VERSION "BMW i3 FlexRay custom draft v3"

NS_ :

BS_:

BU_: BMW_I3

CM_ "Draft DBC derived from BMW i3 FlexRay and PT-CAN logs. Address 27 was not observed in any uploaded segment. Signals below intentionally mix three classes: confirmed parse signals already used by CarState, state/proxy helpers useful for reverse engineering, and unresolved TX candidates kept for shadow-debug correlation.";

BO_ 46 WHEEL_SPEED: 17 BMW_I3
 SG_ WHEEL_SPEED_RAW_WORD_A : 8|16@1+ (1,0) [0|65535] "" BMW_I3
 SG_ WHEEL_SPEED_RAW_WORD_B : 24|16@1+ (1,0) [0|65535] "" BMW_I3
 SG_ WHEEL_SPEED_RAW_WORD_C : 40|16@1+ (1,0) [0|65535] "" BMW_I3
 SG_ WHEEL_SPEED_RAW_WORD_D : 56|16@1+ (1,0) [0|65535] "" BMW_I3
 SG_ RL_SPEED_RAW : 24|16@1+ (0.015625,-511.984375) [0|65535] "kph" BMW_I3
 SG_ RR_SPEED_RAW : 40|16@1+ (0.015625,-511.984375) [0|65535] "kph" BMW_I3
 SG_ FL_SPEED_RAW : 56|16@1+ (0.015625,-511.984375) [0|65535] "kph" BMW_I3
 SG_ FR_SPEED_RAW : 72|16@1+ (0.015625,-511.984375) [0|65535] "kph" BMW_I3
 CM_ BO_ 46 "Confirmed BMW-style wheel-speed helper aligned with the SP2018 bit layout. Wheel speeds remain the secondary/fallback vehicle-speed source in current CarState.";

BO_ 49 STEER_TORQUE: 17 BMW_I3
 SG_ STEER_TORQUE_CYCLE_RAW : 0|8@1+ (1,0) [0|255] "" BMW_I3
 SG_ STEER_TORQUE_RAW_WORD_A : 8|16@1+ (1,0) [0|65535] "" BMW_I3
 SG_ STEER_TORQUE_RAW_WORD_B : 24|16@1+ (1,0) [0|65535] "" BMW_I3
 SG_ STEER_TORQUE_RAW_WORD_C : 40|16@1+ (1,0) [0|65535] "" BMW_I3
 SG_ STEER_TORQUE_RAW_WORD_D : 56|16@1+ (1,0) [0|65535] "" BMW_I3
 SG_ DRIVER_STEER_TORQUE_BMW : 24|12@1+ (0.005,-10) [-10|10.475] "Nm" BMW_I3
 SG_ STEER_TORQUE_STATUS_RAW : 24|8@1+ (1,0) [0|255] "" BMW_I3
 CM_ BO_ 49 "Confirmed steering-torque helper. BMW-style driver torque lives in the 24|12 field and is valid on the cycle-0 subframe. CarState uses this path for steeringTorque/steeringPressed.";

BO_ 51 EPS_ANGLE: 17 BMW_I3
 SG_ EPS_ANGLE_CYCLE_RAW : 0|8@1+ (1,0) [0|255] "" BMW_I3
 SG_ EPS_ANGLE_RAW_WORD_A : 8|16@1+ (1,0) [0|65535] "" BMW_I3
 SG_ EPS_ANGLE_RAW_WORD_B : 24|16@1+ (1,0) [0|65535] "" BMW_I3
 SG_ EPS_ANGLE_RAW_WORD_C : 40|16@1+ (1,0) [0|65535] "" BMW_I3
 SG_ EPS_ANGLE_RAW_WORD_D : 56|16@1+ (1,0) [0|65535] "" BMW_I3
 SG_ EPS_STEERING_ANGLE_BMW : 24|16@1+ (0.0439453125,-1440) [-1440|1440] "deg" BMW_I3
 CM_ BO_ 51 "BMW SP2018-style EPS angle frame aligned to dynm reference work. The m0/cycle-0 subframe carries the steering angle on bytes 3:4 using angle_deg = raw * 0.0439453125 - 1440.0.";
 CM_ SG_ 51 EPS_STEERING_ANGLE_BMW "Primary FlexRay EPS steering-angle candidate aligned to dynm BMW SP2018 reference: steering_angle m0 : 24|16@1+ (0.0439453125,-1440).";

BO_ 55 VEHICLE_SPEED_PROV: 17 BMW_I3
 SG_ VEHICLE_SPEED_CYCLE_RAW M : 0|2@1+ (1,0) [0|3] "" BMW_I3
 SG_ VEHICLE_SPEED_RAW_WORD_A : 8|16@1+ (1,0) [0|65535] "" BMW_I3
 SG_ VEHICLE_SPEED_RAW_WORD_B : 24|16@1+ (1,0) [0|65535] "" BMW_I3
 SG_ VEHICLE_SPEED_RAW_WORD_C : 40|16@1+ (1,0) [0|65535] "" BMW_I3
 SG_ VEHICLE_SPEED_RAW_WORD_D : 56|16@1+ (1,0) [0|65535] "" BMW_I3
 SG_ LONG_ACCEL_RAW m0 : 24|16@1+ (0.002,-65) [0|65535] "" BMW_I3
 SG_ VEHICLE_SPEED_BMW m3 : 24|16@1+ (0.015625,0) [0|65535] "kph" BMW_I3
 SG_ DRIVING_STATUS_BMW m3 : 44|2@1+ (1,0) [0|7] "" BMW_I3
 CM_ BO_ 55 "Confirmed primary vehicle-speed source aligned with the BMW SP2018 multiplexed layout. CarState now consumes the m3 vehicle-speed subframe and keeps frame 46 only as fallback/support.";

BO_ 56 DYNAMICS_YAW_PROV: 17 BMW_I3
 SG_ DYNAMICS_YAW_RAW_WORD_A : 8|16@1+ (1,0) [0|65535] "" BMW_I3
 SG_ DYNAMICS_YAW_RAW_WORD_B : 24|16@1+ (1,0) [0|65535] "" BMW_I3
 SG_ DYNAMICS_YAW_RAW_WORD_C : 40|16@1+ (1,0) [0|65535] "" BMW_I3
 SG_ DYNAMICS_YAW_RAW_WORD_D : 56|16@1+ (1,0) [0|65535] "" BMW_I3
 SG_ YAW_RATE_RAW_A : 8|16@1- (0.01,0) [-500|500] "deg/s" BMW_I3
 SG_ YAW_RATE_RAW_B : 24|16@1- (0.01,0) [-500|500] "deg/s" BMW_I3
 SG_ STEERING_ANGLE_PROXY_56_RAW : 88|16@1+ (1,0) [0|65535] "" BMW_I3
 SG_ STEERING_ANGLE_PROXY_56_DEG : 88|16@1+ (0.0260328634,-851.998806) [-720|720] "deg" BMW_I3
CM_ BO_ 56 "Confirmed vehicle-dynamics helper. Raw yaw fields remain useful for reverse-engineering and stock lateral comparison work. The late word at bytes 11..12 is kept only as a secondary steering-angle debug/support candidate now that frame 51 is promoted.";
CM_ SG_ 56 STEERING_ANGLE_PROXY_56_RAW "Secondary debug/support steering-angle proxy from route 00000402 fitting against PT-CAN 770. Keep for analysis only; no longer the primary steeringAngleDeg source.";
CM_ SG_ 56 STEERING_ANGLE_PROXY_56_DEG "Debug/support steering-angle estimate derived from STEERING_ANGLE_PROXY_56_RAW using the historical fit angle_deg ~= 0.0260328634 * raw56 - 851.998806. Not the primary steeringAngleDeg source anymore.";

BO_ 40 DRIVE_STATE: 17 BMW_I3
 SG_ DRIVE_STATE_CYCLE_COMPAT : 0|2@1+ (1,0) [0|3] "" BMW_I3
 SG_ DRIVE_STATE_RAW : 8|16@1+ (1,0) [0|65535] "" BMW_I3
  SG_ DRIVE_MODE_RAW : 24|8@1+ (1,0) [0|255] "" BMW_I3
 SG_ DRIVE_STATE_GEAR_M3_COMPAT : 24|4@1+ (1,0) [0|15] "" BMW_I3
 SG_ DRIVE_STATE_P_LOCKED_M3_COMPAT : 49|1@1+ (1,0) [0|1] "" BMW_I3
 SG_ DRIVE_STATE_KIND_BYTE_11 : 88|8@1+ (1,0) [0|255] "" BMW_I3
 SG_ DRIVE_STATE_KIND_BYTE_14 : 112|8@1+ (1,0) [0|255] "" BMW_I3
CM_ BO_ 40 "Production drive-state frame. Cross-check against dynm BMW SP2018 FlexRay DBC shows this frame is the closest local match to their maybe_gear_switch frame, and current i3 routes support using its cycle_count plus the byte-11/byte-14 discriminator path as the primary FlexRay gear source in CarState.";

BO_ 44 BRAKE_OR_REGEN_CANDIDATE_A: 17 BMW_I3
 SG_ BRAKE_REGEN_STATE_A : 8|16@1+ (1,0) [0|65535] "" BMW_I3
 SG_ BRAKE_REGEN_STATE_B : 24|16@1+ (1,0) [0|65535] "" BMW_I3
 SG_ EPS_ANGLE_PROXY_44_RAW : 105|12@1- (1,0) [-2048|2047] "" BMW_I3
 SG_ EPS_ANGLE_PROXY_44_DEG : 105|12@1- (0.0835794,3.3976) [-720|720] "deg" BMW_I3
 CM_ SG_ 44 BRAKE_REGEN_STATE_A "Experimental secondary longitudinal candidate. Across historical TJA routes 00000054/55 and modern ACC-only route 000000b3, this frame separates dynamic phases weakly but remains far less informative than 54 and 59 for manual pedal vs managed-following behavior.";
CM_ SG_ 44 EPS_ANGLE_PROXY_44_RAW "Legacy experimental steering-angle proxy from earlier route fitting. Keep for debug only. Recent whole-route checks show it often stays nearly flat and it is no longer used for steeringAngleDeg.";
CM_ SG_ 44 EPS_ANGLE_PROXY_44_DEG "Legacy debug-only steering-angle estimate derived from EPS_ANGLE_PROXY_44_RAW. No production steeringAngleDeg use.";

BO_ 54 BRAKE_BLEND_CANDIDATE_B: 17 BMW_I3
 SG_ LONG_TX_BRAKE_BLEND_PHASE_BYTE_0 : 0|8@1+ (1,0) [0|255] "" BMW_I3
 SG_ BRAKE_BLEND_STATE_A : 8|16@1+ (1,0) [0|65535] "" BMW_I3
 SG_ BRAKE_BLEND_STATE_B : 24|16@1+ (1,0) [0|65535] "" BMW_I3
 SG_ BRAKE_BLEND_STATE_C : 40|16@1+ (1,0) [0|65535] "" BMW_I3
 SG_ LONG_TX_BRAKE_BLEND_WORD_B : 24|16@1+ (1,0) [0|65535] "" BMW_I3
 SG_ LONG_TX_BRAKE_BLEND_WORD_C : 40|16@1+ (1,0) [0|65535] "" BMW_I3
 SG_ BRAKE_BLEND_BYTE_3 : 24|8@1+ (1,0) [0|255] "" BMW_I3
 SG_ BRAKE_BLEND_BYTE_4 : 32|8@1+ (1,0) [0|255] "" BMW_I3
 SG_ BRAKE_BLEND_BYTE_5 : 40|8@1+ (1,0) [0|255] "" BMW_I3
 SG_ BRAKE_BLEND_BYTE_6 : 48|8@1+ (1,0) [0|255] "" BMW_I3
 SG_ LONG_TX_BRAKE_BLEND_BYTE_4 : 32|8@1+ (1,0) [0|255] "" BMW_I3
 SG_ LONG_TX_BRAKE_BLEND_BYTE_6 : 48|8@1+ (1,0) [0|255] "" BMW_I3
CM_ SG_ 54 BRAKE_BLEND_STATE_A "Primary brake-blend / regen-support candidate. Across 00000054, 00000055, modern ACC-only route 000000b3, and recent ACC-only route 00000147, this frame cleanly separates manual accelerator application, ACC armed/base, and managed/following phases. STATE_B and STATE_C rise strongly in managed-following and automatic decel windows. In 00000147, frame 54 becomes active in complementary subframes while 59 carries the powertrain-intent side, reinforcing that 54 is the best current stock longitudinal support frame for brake-blend / regen behavior rather than a standalone brake command.";
CM_ SG_ 54 LONG_TX_BRAKE_BLEND_PHASE_BYTE_0 "Best current transport/phase byte for frame 54. Managed windows show a strong byte-level cycle with a counter-like low nibble, indicating housekeeping/phase structure rather than direct command magnitude.";
CM_ SG_ 54 LONG_TX_BRAKE_BLEND_WORD_B "Best current negative-branch TX candidate. In managed ACC windows it is the dominant non-idle content when desired longitudinal behavior is decel / regen / brake-blend. Current conservative replay interpretation: use this family on the negative branch, primarily on odd/every-other managed subcycles, centered near 65025.";
CM_ SG_ 54 LONG_TX_BRAKE_BLEND_WORD_C "Companion word to LONG_TX_BRAKE_BLEND_WORD_B. Best current negative-branch TX candidate alongside frame 54 word B. Current conservative replay interpretation: use this family on the negative branch, primarily on odd/every-other managed subcycles, centered near 7.";
CM_ SG_ 54 LONG_TX_BRAKE_BLEND_BYTE_4 "Low byte of the current best frame-54 negative-branch TX word. Useful for byte-local replay fitting and checksum/counter separation work.";
CM_ SG_ 54 LONG_TX_BRAKE_BLEND_BYTE_6 "Low byte of the current best frame-54 companion TX word. Useful for byte-local replay fitting and checksum/counter separation work.";

BO_ 59 PEDAL_OR_HOLD_STATE_CANDIDATE: 17 BMW_I3
 SG_ LONG_TX_POWERTRAIN_PHASE_BYTE_0 : 0|8@1+ (1,0) [0|255] "" BMW_I3
 SG_ PEDAL_HOLD_STATE_RAW : 16|16@1+ (1,0) [0|65535] "" BMW_I3
 SG_ PEDAL_HOLD_STATE_AUX : 32|16@1+ (1,0) [0|65535] "" BMW_I3
 SG_ PEDAL_HOLD_BYTE_2 : 16|8@1+ (1,0) [0|255] "" BMW_I3
 SG_ PEDAL_HOLD_BYTE_3 : 24|8@1+ (1,0) [0|255] "" BMW_I3
 SG_ PEDAL_HOLD_BYTE_4 : 32|8@1+ (1,0) [0|255] "" BMW_I3
 SG_ PEDAL_HOLD_BYTE_5 : 40|8@1+ (1,0) [0|255] "" BMW_I3
 SG_ LONG_TX_POWERTRAIN_WORD_B : 24|16@1+ (1,0) [0|65535] "" BMW_I3
 SG_ LONG_TX_POWERTRAIN_WORD_C : 40|16@1+ (1,0) [0|65535] "" BMW_I3
 SG_ LONG_TX_POWERTRAIN_BYTE_3 : 24|8@1+ (1,0) [0|255] "" BMW_I3
 SG_ LONG_TX_POWERTRAIN_BYTE_5 : 40|8@1+ (1,0) [0|255] "" BMW_I3
CM_ SG_ 59 PEDAL_HOLD_STATE_RAW "Strongest stock longitudinal content candidate so far. Across 00000054, 00000055, 000000b3, and recent ACC-only route 00000147, RAW is high during clear manual accelerator application, lower in ACC armed/base, and lowest during managed/following windows. AUX also shifts strongly between manual and managed phases. In 00000147 managed ACC, 59 remains the dominant powertrain-intent family while 54 appears in complementary brake-blend subframes. This remains the best current candidate for stock pedal/hold/coast-state inference under ACC, not a closed accel command.";
CM_ SG_ 59 LONG_TX_POWERTRAIN_PHASE_BYTE_0 "Best current transport/phase byte for frame 59. Managed windows show a strong byte-level cycle with a counter-like low nibble, indicating housekeeping/phase structure rather than direct command magnitude.";
CM_ SG_ 59 LONG_TX_POWERTRAIN_WORD_B "Best current positive/coast TX candidate. In managed ACC windows it is the dominant non-idle content when desired longitudinal behavior is propulsion / hold / coast rather than brake-blend. Current conservative replay interpretation: use this family on the positive-or-coast branch, primarily on even/every-other managed subcycles, centered near 32777.";
CM_ SG_ 59 LONG_TX_POWERTRAIN_WORD_C "Companion word to LONG_TX_POWERTRAIN_WORD_B. Best current positive/coast TX candidate alongside frame 59 word B. Current conservative replay interpretation: use this family on the positive-or-coast branch, primarily on even/every-other managed subcycles, centered near 32767.";
CM_ SG_ 59 LONG_TX_POWERTRAIN_BYTE_3 "Low byte of the current best frame-59 positive/coast TX word. Useful for byte-local replay fitting and checksum/counter separation work.";
CM_ SG_ 59 LONG_TX_POWERTRAIN_BYTE_5 "Low byte of the current best frame-59 companion TX word. Useful for byte-local replay fitting and checksum/counter separation work.";

BO_ 60 LAT_STOCK_TX_TRIGGER_CANDIDATE: 17 BMW_I3
 SG_ LAT_STOCK_TRIGGER_PHASE_BYTE_0 : 0|8@1+ (1,0) [0|255] "" BMW_I3
 SG_ LAT_STOCK_TRIGGER_SUBFRAME_LSB : 0|2@1+ (1,0) [0|3] "" BMW_I3
 SG_ LAT_STOCK_TRIGGER_CMD_PHASE : 1|5@1+ (1,0) [0|31] "" BMW_I3
CM_ BO_ 60 "Primary SAS-side predecessor/trigger for lateral frame 72 on the i3. Latest realdata plus the dynm-style firmware path show the stock SAS emits the lateral stream as a paired burst on src0: 60 -> 72, repeated across four subframes every ~20 ms macro tick. Frame 60 is structurally near-empty outside byte0, so treat it as the scheduler/trigger half of the burst, not the analog steering payload.";
CM_ SG_ 60 LAT_STOCK_TRIGGER_PHASE_BYTE_0 "Raw scheduler byte for the SAS-side predecessor of frame 72. This byte advances through the same burst order seen on 72 and is the practical trigger byte for firmware-aligned injection work.";
CM_ SG_ 60 LAT_STOCK_TRIGGER_SUBFRAME_LSB "Low two bits of frame-60 byte0. Useful when reconstructing the four-subframe burst order observed in the SAS 20 ms lateral scheduler.";
CM_ SG_ 60 LAT_STOCK_TRIGGER_CMD_PHASE "Derived command-phase view of frame-60 byte0 (byte0 >> 1). Use together with frame 72 when checking whether the trigger/control pair stays on the same phase orbit.";

BO_ 72 LAT_STOCK_TX_CANDIDATE: 17 BMW_I3
 SG_ LAT_STOCK_TX_PHASE_BYTE_0 : 0|8@1+ (1,0) [0|255] "" BMW_I3
 SG_ LAT_STOCK_TX_CNT_NIBBLE : 16|4@1+ (1,0) [0|15] "" BMW_I3
 SG_ LAT_STOCK_TX_CONST_F_NIBBLE : 20|4@1+ (1,0) [0|15] "" BMW_I3
 SG_ LAT_STOCK_TX_FLAG_BYTE_8 : 64|8@1+ (1,0) [0|255] "" BMW_I3
CM_ BO_ 72 "Primary stock lateral control frame on the i3 SAS side. Firmware and route work now point to a paired burst architecture rather than a standalone 72 stream: every ~20 ms macro scheduler tick emits a 60 -> 72 burst across four subframes on src0. The i3 raw capture still does not expose a simple analog angle field directly; the best practical decode remains discrete and phase-local. Use byte0 as the outer phase/subframe selector and byte2 low nibble as the command-state companion. The most useful raw proxy found so far is (phase = byte0 >> 1, nibble = byte2 low nibble), with orbit checks around nibble ~= phase + 3 / phase + 4 (mod 16). Byte8 remains structurally fixed at 0xE0 in current captures.";
CM_ SG_ 72 LAT_STOCK_TX_PHASE_BYTE_0 "Primary phase/subframe byte for stock lateral frame 72. Current best route-backed decode uses phase = byte0 >> 1 plus subframe splitting, not byte0 itself as steering magnitude.";
CM_ SG_ 72 LAT_STOCK_TX_CNT_NIBBLE "Low nibble of byte2 in stock lateral frame 72. This is the key discrete command-state companion. Together with phase = (byte0 >> 1), it forms the best current raw orbit proxy for future steering response.";
CM_ SG_ 72 LAT_STOCK_TX_CONST_F_NIBBLE "Constant high nibble 0xF in the lateral TX envelope byte pair. Treat as structural filler/format marker rather than command content.";
CM_ SG_ 72 LAT_STOCK_TX_FLAG_BYTE_8 "Structurally stable tail byte, usually 0xE0 in current captures. Treat as fixed envelope/flag content unless future replay work proves otherwise.";

BO_ 43 CHASSIS_STATE_CANDIDATE: 17 BMW_I3
 SG_ CHASSIS_STATE_A : 8|16@1+ (1,0) [0|65535] "" BMW_I3
 SG_ CHASSIS_STATE_B : 24|16@1+ (1,0) [0|65535] "" BMW_I3
 CM_ SG_ 43 CHASSIS_STATE_A "Experimental secondary dynamic-state frame. It follows longitudinal phase changes across 00000054/55/b3, but is still weaker than 59 and 54 for isolating stock ACC content.";

BO_ 63 LONG_STATE_HELPER_D: 17 BMW_I3
 SG_ LONG_STATE_HELPER_D_WORD_A : 8|16@1+ (1,0) [0|65535] "" BMW_I3
 SG_ LONG_STATE_HELPER_D_WORD_B : 24|16@1+ (1,0) [0|65535] "" BMW_I3
 SG_ LONG_STATE_HELPER_D_WORD_C : 40|16@1+ (1,0) [0|65535] "" BMW_I3
 SG_ LONG_STATE_HELPER_D_WORD_D : 56|16@1+ (1,0) [0|65535] "" BMW_I3
 CM_ BO_ 63 "Raw helper added after route 000003d0 showed src1/63 as one of the strongest discriminants for stock longitudinal frame families 54/59. Keep read-only for state-machine closure; do not treat as a direct accel command.";

BO_ 93 ACC_TJA_OLD_ROUTE_HELPER_A: 17 BMW_I3
 SG_ ACC_TJA_OLD_A_CYCLE : 0|8@1+ (1,0) [0|255] "" BMW_I3
 SG_ LONG_STATE_HELPER_A_WORD_A : 8|16@1+ (1,0) [0|65535] "" BMW_I3
 SG_ LONG_STATE_HELPER_A_WORD_B : 24|16@1+ (1,0) [0|65535] "" BMW_I3
 SG_ LONG_STATE_HELPER_A_WORD_C : 40|16@1+ (1,0) [0|65535] "" BMW_I3
 SG_ LONG_STATE_HELPER_A_WORD_D : 56|16@1+ (1,0) [0|65535] "" BMW_I3
 SG_ ACC_TJA_OLD_A_WORD_A : 8|16@1+ (1,0) [0|65535] "" BMW_I3
 SG_ ACC_TJA_OLD_A_WORD_B : 24|16@1+ (1,0) [0|65535] "" BMW_I3
 SG_ ACC_TJA_OLD_A_WORD_C : 40|16@1+ (1,0) [0|65535] "" BMW_I3
 SG_ ACC_TJA_OLD_A_WORD_D : 56|16@1+ (1,0) [0|65535] "" BMW_I3
 SG_ ACC_TJA_OLD_STATE_MAIN_A : 40|16@1+ (1,0) [0|65535] "" BMW_I3
 CM_ BO_ 93 "Experimental helper from legacy multi-segment TJA routes 00000054/55/56. This src23 frame repeatedly changed around ACC/TJA/stalk command windows and is kept as a raw helper only for old-route correlation.";

BO_ 96 LAT_STOCK_TX_PAYLOAD_CANDIDATE: 9 BMW_I3
 SG_ LAT_STOCK_TX_PAYLOAD_BYTE_0 : 0|8@1+ (1,0) [0|255] "" BMW_I3
 SG_ LAT_STOCK_TX_PAYLOAD_BYTE_1 : 8|8@1+ (1,0) [0|255] "" BMW_I3
 SG_ LAT_STOCK_TX_PAYLOAD_BYTE_2 : 16|8@1+ (1,0) [0|255] "" BMW_I3
 SG_ LAT_STOCK_TX_PAYLOAD_BYTE_3 : 24|8@1+ (1,0) [0|255] "" BMW_I3
 SG_ LAT_STOCK_TX_PAYLOAD_BYTE_4 : 32|8@1+ (1,0) [0|255] "" BMW_I3
 SG_ LAT_STOCK_TX_PAYLOAD_BYTE_8 : 64|8@1+ (1,0) [0|255] "" BMW_I3
CM_ BO_ 96 "Primary lateral TX payload candidate. Routes 000000e9 and 000000ea provide the first labeled left/right windows; route 00000176 added dense managed-TJA coverage; route 00000402 (2026-03-27 TJA-only labeling pass) tightened the current practical decoder. Across all of them, src0/96 changes coherently during assisted-steering windows while src0/72 behaves like the outer TX phase/counter envelope. Current best practical decoder is phase-local on (72.byte0, 96.byte1), not a global scale in degrees. High-value phases where right means higher byte1 (R_high): phase 57 L/C/R ~ 63/174.5/236, phase 35 ~ 99/174.5/236, phase 49 ~ 81/175/217, phase 46 ~ 99/157/216. High-value phases where right means lower byte1 (R_low): phase 58 ~ 196.5/174.5/62, phase 25 ~ 176.5/110/62. Treat 96.byte2 as secondary torque/intensity-like support only. This frame remains the best current candidate for the actual stock lateral TX payload, but full command semantics are still unresolved.";
CM_ SG_ 96 LAT_STOCK_TX_PAYLOAD_BYTE_0 "Secondary phase/family byte inside the current best lateral TX payload frame. Useful for phase-local grouping together with frame 72 and byte1.";
CM_ SG_ 96 LAT_STOCK_TX_PAYLOAD_BYTE_1 "Best current direction-discriminating byte in the stock lateral TX payload. Decode only phase-locally with 72.byte0. Current strongest phases from route 00000402 are: R_high -> phase 57 (L/C/R ~ 63/174.5/236), phase 35 (99/174.5/236), phase 49 (81/175/217), phase 46 (99/157/216); R_low -> phase 58 (196.5/174.5/62), phase 25 (176.5/110/62). Do not treat byte1 as a global signed angle scale; the same numeric direction flips across phase families.";
CM_ SG_ 96 LAT_STOCK_TX_PAYLOAD_BYTE_2 "Auxiliary payload byte that moves with steering activity but is not yet isolated as a standalone signed magnitude. Relative to dynm/smnogar BMW SP2018 references, byte2 is the best current i3 candidate for a torque/intensity-like companion to byte1, but it is weaker than byte1 and should not be used as the primary direction discriminator.";
CM_ SG_ 96 LAT_STOCK_TX_PAYLOAD_BYTE_3 "Payload-support byte that remains structurally stable across many managed windows. Useful for identifying fixed-vs-dynamic portions of frame 96.";
CM_ SG_ 96 LAT_STOCK_TX_PAYLOAD_BYTE_4 "Payload-support byte that remains structurally stable across many managed windows. Useful for identifying fixed-vs-dynamic portions of frame 96.";
CM_ SG_ 96 LAT_STOCK_TX_PAYLOAD_BYTE_8 "Tail byte in the current best lateral TX payload frame. Keep as raw structural content until checksum/counter separation is proven.";

BO_ 97 ACC_TJA_OLD_ROUTE_HELPER_B: 17 BMW_I3
 SG_ ACC_TJA_OLD_B_CYCLE : 0|8@1+ (1,0) [0|255] "" BMW_I3
 SG_ ACC_TJA_OLD_B_WORD_A : 8|16@1+ (1,0) [0|65535] "" BMW_I3
 SG_ ACC_TJA_OLD_B_WORD_B : 24|16@1+ (1,0) [0|65535] "" BMW_I3
 SG_ ACC_TJA_OLD_B_WORD_C : 40|16@1+ (1,0) [0|65535] "" BMW_I3
 SG_ ACC_TJA_OLD_B_WORD_D : 56|16@1+ (1,0) [0|65535] "" BMW_I3
 SG_ ACC_TJA_OLD_STALK_MAIN_A : 8|16@1+ (1,0) [0|65535] "" BMW_I3
 SG_ ACC_TJA_OLD_STALK_MAIN_B : 24|16@1+ (1,0) [0|65535] "" BMW_I3
 CM_ BO_ 97 "Experimental helper from legacy multi-segment TJA routes 00000054/55/56. This src23 frame is one of the strongest recurring candidates for ACC/TJA/stalk command state and is exposed raw for old-route analysis.";

BO_ 102 COLUMN_SWITCH_CANDIDATE: 17 BMW_I3
 SG_ COLUMN_SWITCH_WORD_A : 8|16@1+ (1,0) [0|65535] "" BMW_I3
 SG_ COLUMN_SWITCH_WORD_B : 24|16@1+ (1,0) [0|65535] "" BMW_I3
 SG_ COLUMN_SWITCH_WORD_C : 40|16@1+ (1,0) [0|65535] "" BMW_I3
 SG_ COLUMN_SWITCH_WORD_D : 56|16@1+ (1,0) [0|65535] "" BMW_I3
 CM_ BO_ 102 "Experimental column-switch / indicator candidate. In the parked command-isolation route, this frame changed clearly during right/left indicator windows and also moved with some ACC/TJA button presses. Treat as a likely steering-column input frame rather than pure ADAS state.";

BO_ 110 ACC_TJA_OLD_ROUTE_HELPER_C: 17 BMW_I3
 SG_ ACC_TJA_OLD_C_CYCLE : 0|8@1+ (1,0) [0|255] "" BMW_I3
 SG_ ACC_TJA_OLD_C_WORD_A : 8|16@1+ (1,0) [0|65535] "" BMW_I3
 SG_ ACC_TJA_OLD_C_WORD_B : 24|16@1+ (1,0) [0|65535] "" BMW_I3
 SG_ ACC_TJA_OLD_C_WORD_C : 40|16@1+ (1,0) [0|65535] "" BMW_I3
 SG_ ACC_TJA_OLD_C_WORD_D : 56|16@1+ (1,0) [0|65535] "" BMW_I3
 CM_ BO_ 110 "Experimental helper from legacy multi-segment TJA routes 00000054/55/56. This src23 frame moved with speed-stalk and ACC transitions often enough to warrant a raw helper block.";

BO_ 106 ACC_STALK_TJA_CANDIDATE_A: 17 BMW_I3
 SG_ ACC_STALK_TJA_WORD_A : 8|16@1+ (1,0) [0|65535] "" BMW_I3
 SG_ ACC_STALK_TJA_WORD_B : 24|16@1+ (1,0) [0|65535] "" BMW_I3
 SG_ ACC_STALK_TJA_WORD_C : 40|16@1+ (1,0) [0|65535] "" BMW_I3
 SG_ ACC_STALK_TJA_WORD_D : 56|16@1+ (1,0) [0|65535] "" BMW_I3
 CM_ BO_ 106 "Experimental ACC/TJA candidate from TJA and parked command-isolation routes. Changed coherently around SET, RES, ACC, TJA, speed-stalk increment/decrement, distance-button, and ACC off windows. Byte pair around bits 24..39 stayed stable enough for comparison across sessions, but no clean bit-level interpretation is confirmed yet.";

BO_ 112 ACC_STALK_TJA_CANDIDATE_B: 17 BMW_I3
 SG_ ACC_STALK_TJA_B_WORD_A : 8|16@1+ (1,0) [0|65535] "" BMW_I3
 SG_ ACC_STALK_TJA_B_WORD_B : 24|16@1+ (1,0) [0|65535] "" BMW_I3
 SG_ ACC_STALK_TJA_B_WORD_C : 40|16@1+ (1,0) [0|65535] "" BMW_I3
 SG_ ACC_STALK_TJA_B_WORD_D : 56|16@1+ (1,0) [0|65535] "" BMW_I3
 SG_ LAT_STOCK_MAIN_BYTE_0 : 0|8@1+ (1,0) [0|255] "" BMW_I3
 SG_ LAT_STOCK_MAIN_BYTE_1 : 8|8@1+ (1,0) [0|255] "" BMW_I3
 SG_ LAT_STOCK_MAIN_WORD_A : 8|16@1+ (1,0) [0|65535] "" BMW_I3
 SG_ LAT_STOCK_MAIN_WORD_B : 24|16@1+ (1,0) [0|65535] "" BMW_I3
 SG_ LAT_STOCK_MAIN_WORD_C : 40|16@1+ (1,0) [0|65535] "" BMW_I3
 SG_ LAT_STOCK_MAIN_WORD_D : 56|16@1+ (1,0) [0|65535] "" BMW_I3
 SG_ LAT_STOCK_MAIN_BYTE_5 : 40|8@1+ (1,0) [0|255] "" BMW_I3
 SG_ LAT_STOCK_ACTIVE_HINT : 45|1@1+ (1,0) [0|1] "" BMW_I3
CM_ BO_ 112 "Primary lateral RX/state helper. Confirmed on historical routes 00000054 and 00000055 and reinforced by managed-TJA route 00000176. Historical logs exposed it on src24; modern dual-FlexRay logging exposes the same frame on src1. It changes cleanly between manual driving, ACC-base, and TJA-assisted steering windows and is the best current candidate for reverse-engineering stock lateral control state/content. Byte5 bit5 is the strongest live discriminator: off/manual tends to set the bit, assisted steering tends to clear it. CarState now uses this as the live stock_lat_active_hint gate before trusting the phase-local 96 direction hint.";
CM_ SG_ 112 LAT_STOCK_MAIN_BYTE_5 "Best current live assisted-steering state discriminator. Bit5 set tends to mean manual/off; bit5 clear tends to mean assisted/TJA-active. CarState uses this to gate the phase-local 96 direction hint.";
CM_ SG_ 112 LAT_STOCK_ACTIVE_HINT "Derived boolean helper from LAT_STOCK_MAIN_BYTE_5 bit5. 1 means the stock lateral system appears active enough to trust 96 direction hints; 0 means suppress direction to unknown.";

BO_ 116 ACC_STALK_TJA_CANDIDATE_C: 17 BMW_I3
 SG_ ACC_STALK_TJA_C_WORD_A : 8|16@1+ (1,0) [0|65535] "" BMW_I3
 SG_ ACC_STALK_TJA_C_WORD_B : 24|16@1+ (1,0) [0|65535] "" BMW_I3
 SG_ ACC_STALK_TJA_C_WORD_C : 40|16@1+ (1,0) [0|65535] "" BMW_I3
 SG_ ACC_STALK_TJA_C_WORD_D : 56|16@1+ (1,0) [0|65535] "" BMW_I3
 SG_ LAT_STOCK_SUPPORT_WORD_A : 8|16@1+ (1,0) [0|65535] "" BMW_I3
 SG_ LAT_STOCK_SUPPORT_WORD_B : 24|16@1+ (1,0) [0|65535] "" BMW_I3
 SG_ LAT_STOCK_SUPPORT_WORD_C : 40|16@1+ (1,0) [0|65535] "" BMW_I3
 SG_ LAT_STOCK_SUPPORT_WORD_D : 56|16@1+ (1,0) [0|65535] "" BMW_I3
 SG_ LAT_STOCK_SUPPORT_BYTE_1 : 8|8@1+ (1,0) [0|255] "" BMW_I3
 SG_ LAT_STOCK_SUPPORT_BYTE_2 : 16|8@1+ (1,0) [0|255] "" BMW_I3
 SG_ LAT_STOCK_SUPPORT_BYTE_5 : 40|8@1+ (1,0) [0|255] "" BMW_I3
CM_ BO_ 116 "Secondary lateral RX/state helper. Confirmed on historical routes 00000054 and 00000055, present on the modern interface in route 000000b3, and strengthened by managed-TJA route 00000176. Historical logs exposed it on src23; modern dual-FlexRay logging exposes the same frame on src1. It tracks the same assisted-steering phases as 112 and is the best current secondary helper for stock lateral command/echo analysis. Byte5 is not yet a standalone boolean, but it moves through stable phase families alongside 112 and is logged as support evidence for the live stock_lat_active_hint path.";
CM_ SG_ 116 LAT_STOCK_SUPPORT_BYTE_5 "Secondary state-support byte for stock lateral activity. Not yet a standalone boolean, but it moves through stable phase families alongside frame 112 and is useful as corroborating evidence when validating assisted-steering windows.";

BO_ 124 ACC_STALK_TJA_CANDIDATE_D: 17 BMW_I3
 SG_ ACC_STALK_TJA_D_WORD_A : 8|16@1+ (1,0) [0|65535] "" BMW_I3
 SG_ ACC_STALK_TJA_D_WORD_B : 24|16@1+ (1,0) [0|65535] "" BMW_I3
 SG_ ACC_STALK_TJA_D_WORD_C : 40|16@1+ (1,0) [0|65535] "" BMW_I3
 SG_ ACC_STALK_TJA_D_WORD_D : 56|16@1+ (1,0) [0|65535] "" BMW_I3
 CM_ BO_ 124 "Experimental ACC/TJA candidate from TJA and parked command-isolation routes. Strongly correlated with SET, RES, ACC, TJA, speed-stalk increment/decrement, distance-button, and ACC off. This frame is a priority candidate for future bit-level extraction of ACC/TJA state.";

BO_ 131 ACC_TJA_OLD_ROUTE_HELPER_D: 17 BMW_I3
 SG_ ACC_TJA_OLD_D_CYCLE : 0|8@1+ (1,0) [0|255] "" BMW_I3
 SG_ ACC_TJA_OLD_D_WORD_A : 8|16@1+ (1,0) [0|65535] "" BMW_I3
 SG_ ACC_TJA_OLD_D_WORD_B : 24|16@1+ (1,0) [0|65535] "" BMW_I3
 SG_ ACC_TJA_OLD_D_WORD_C : 40|16@1+ (1,0) [0|65535] "" BMW_I3
 SG_ ACC_TJA_OLD_D_WORD_D : 56|16@1+ (1,0) [0|65535] "" BMW_I3
 SG_ ACC_TJA_OLD_CTRL_GATE : 40|16@1+ (1,0) [0|65535] "" BMW_I3
 SG_ ACC_LONG_GATE_STATE : 40|16@1+ (1,0) [0|65535] "" BMW_I3
CM_ BO_ 131 "Primary longitudinal state/gate helper. Legacy routes and the current three-way comparison set 000003ff (manual), 00000400 (ACC-only), and 00000402 (ACC+TJA) confirm that 131 separates manual-driving families from ACC/TJA session families, but does not by itself cleanly split ACC-only from TJA. Manual families still sit in the older ...9883/ba83/b98302ffff space, while both ACC-only and TJA move into the newer ...00000effff / ...7c-7f8002ffff family. Treat 131 as the coarse ACC/TJA family gate, not the final TJA discriminator.";

BO_ 135 ACC_TJA_OLD_ROUTE_HELPER_E: 17 BMW_I3
 SG_ ACC_TJA_OLD_E_CYCLE : 0|8@1+ (1,0) [0|255] "" BMW_I3
 SG_ ACC_TJA_OLD_E_WORD_A : 8|16@1+ (1,0) [0|65535] "" BMW_I3
 SG_ ACC_TJA_OLD_E_WORD_B : 24|16@1+ (1,0) [0|65535] "" BMW_I3
 SG_ ACC_TJA_OLD_E_WORD_C : 40|16@1+ (1,0) [0|65535] "" BMW_I3
 SG_ ACC_TJA_OLD_E_WORD_D : 56|16@1+ (1,0) [0|65535] "" BMW_I3
 SG_ ACC_TJA_OLD_CTRL_STATE : 40|16@1+ (1,0) [0|65535] "" BMW_I3
 SG_ ACC_LONG_MAIN_STATE : 40|16@1+ (1,0) [0|65535] "" BMW_I3
CM_ BO_ 135 "Primary longitudinal/lateral session-state helper, but no longer a single rigid TJA gate. Historical labeling from 000003ff/00000400/00000402 still holds for the older families: manual -> ...22e0e188a205, ACC-only -> ...2228e260a205, older TJA -> ...2228e2604206 / ...20e0e2403206. Newer realdata route 00000006--e6a3e58043 shows additional valid managed-TJA families that do not fit the old 4206-only rule, especially ...20e0e240e201, ...2228e260e201, ...2228e2608202, and ...2228e2408202. Use 135 together with the 60->72 burst behavior when classifying stock lateral context; 135 alone is no longer sufficient to declare ACC-only vs TJA on newer routes.";

BO_ 241 ACC_TJA_OLD_ROUTE_HELPER_F: 17 BMW_I3
 SG_ ACC_TJA_OLD_F_CYCLE : 0|8@1+ (1,0) [0|255] "" BMW_I3
 SG_ ACC_TJA_OLD_F_WORD_A : 8|16@1+ (1,0) [0|65535] "" BMW_I3
 SG_ ACC_TJA_OLD_F_WORD_B : 24|16@1+ (1,0) [0|65535] "" BMW_I3
 SG_ ACC_TJA_OLD_F_WORD_C : 40|16@1+ (1,0) [0|65535] "" BMW_I3
 SG_ ACC_TJA_OLD_F_WORD_D : 56|16@1+ (1,0) [0|65535] "" BMW_I3
 CM_ BO_ 241 "Experimental helper from legacy multi-segment TJA routes 00000054/55/56. Secondary command-related frame retained as raw helper for ACC/TJA comparison work.";

BO_ 250 ACC_TJA_OLD_ROUTE_HELPER_G: 17 BMW_I3
 SG_ ACC_TJA_OLD_G_CYCLE : 0|8@1+ (1,0) [0|255] "" BMW_I3
 SG_ ACC_TJA_OLD_G_WORD_A : 8|16@1+ (1,0) [0|65535] "" BMW_I3
 SG_ ACC_TJA_OLD_G_WORD_B : 24|16@1+ (1,0) [0|65535] "" BMW_I3
 SG_ ACC_TJA_OLD_G_WORD_C : 40|16@1+ (1,0) [0|65535] "" BMW_I3
 SG_ ACC_TJA_OLD_G_WORD_D : 56|16@1+ (1,0) [0|65535] "" BMW_I3
 CM_ BO_ 250 "Experimental helper from legacy multi-segment TJA routes 00000054/55/56. Strong secondary responder during SET/RES/ACC/TJA/speed-stalk windows; kept raw for old-route correlation.";

BO_ 256 ACC_STALK_TJA_CANDIDATE_E: 17 BMW_I3
 SG_ ACC_STALK_TJA_E_WORD_A : 8|16@1+ (1,0) [0|65535] "" BMW_I3
 SG_ ACC_STALK_TJA_E_WORD_B : 24|16@1+ (1,0) [0|65535] "" BMW_I3
 SG_ ACC_STALK_TJA_E_WORD_C : 40|16@1+ (1,0) [0|65535] "" BMW_I3
 CM_ BO_ 256 "Experimental ACC/TJA candidate from TJA and parked command-isolation routes. Small payload frame that changed consistently at SET, RES, ACC, TJA, speed-stalk increment/decrement, distance-button, blinker windows, and ACC off. Good candidate for compact command-state or resume-state signaling.";

BO_ 269 ACC_TJA_OLD_ROUTE_HELPER_H: 17 BMW_I3
 SG_ ACC_TJA_OLD_H_CYCLE : 0|8@1+ (1,0) [0|255] "" BMW_I3
 SG_ ACC_TJA_OLD_H_WORD_A : 8|16@1+ (1,0) [0|65535] "" BMW_I3
 SG_ ACC_TJA_OLD_H_WORD_B : 24|16@1+ (1,0) [0|65535] "" BMW_I3
 SG_ ACC_TJA_OLD_H_WORD_C : 40|16@1+ (1,0) [0|65535] "" BMW_I3
 SG_ ACC_TJA_OLD_H_WORD_D : 56|16@1+ (1,0) [0|65535] "" BMW_I3
 CM_ BO_ 269 "Experimental helper from legacy multi-segment TJA routes 00000054/55/56. Src13 frame that reacts strongly near ACC/TJA engagement and manual intervention windows.";

BO_ 271 ACC_TJA_OLD_ROUTE_HELPER_I: 17 BMW_I3
 SG_ ACC_TJA_OLD_I_CYCLE : 0|8@1+ (1,0) [0|255] "" BMW_I3
 SG_ ACC_TJA_OLD_I_WORD_A : 8|16@1+ (1,0) [0|65535] "" BMW_I3
 SG_ ACC_TJA_OLD_I_WORD_B : 24|16@1+ (1,0) [0|65535] "" BMW_I3
 SG_ ACC_TJA_OLD_I_WORD_C : 40|16@1+ (1,0) [0|65535] "" BMW_I3
 SG_ ACC_TJA_OLD_I_WORD_D : 56|16@1+ (1,0) [0|65535] "" BMW_I3
 CM_ BO_ 271 "Experimental helper from legacy multi-segment TJA routes 00000054/55/56. Src13 frame that follows the same command-family transitions as 135/97/116/112/275, but with weaker consistency.";

BO_ 275 ACC_STALK_TJA_CANDIDATE_F: 17 BMW_I3
 SG_ ACC_STALK_TJA_F_WORD_A : 8|16@1+ (1,0) [0|65535] "" BMW_I3
 SG_ ACC_STALK_TJA_F_WORD_B : 24|16@1+ (1,0) [0|65535] "" BMW_I3
 SG_ ACC_STALK_TJA_F_WORD_C : 40|16@1+ (1,0) [0|65535] "" BMW_I3
 SG_ ACC_STALK_TJA_F_WORD_D : 56|16@1+ (1,0) [0|65535] "" BMW_I3
 SG_ LAT_STOCK_CONFIRM_WORD_A : 8|16@1+ (1,0) [0|65535] "" BMW_I3
 SG_ LAT_STOCK_CONFIRM_WORD_B : 24|16@1+ (1,0) [0|65535] "" BMW_I3
 SG_ LAT_STOCK_CONFIRM_WORD_C : 40|16@1+ (1,0) [0|65535] "" BMW_I3
 SG_ LAT_STOCK_CONFIRM_WORD_D : 56|16@1+ (1,0) [0|65535] "" BMW_I3
 CM_ BO_ 275 "Stock lateral/TJA confirmation helper confirmed on historical routes 00000054 and 00000055 and present on the modern interface in route 000000b3. Historical logs exposed it on src23; modern dual-FlexRay logging exposes the same frame on src1. It is less clean than 112 and 116 but moves consistently with assisted-steering phases and is useful as a third correlation frame.";

BO_ 217 PTCAN_ACCELERATOR_CANDIDATE: 8 BMW_I3
 SG_ ACCEL_RAW_PT_CAN : 0|16@1+ (1,0) [0|65535] "" BMW_I3
 SG_ ACCEL_BYTE_0_PT_CAN : 0|8@1+ (1,0) [0|255] "" BMW_I3
 SG_ ACCEL_BYTE_1_PT_CAN : 8|8@1+ (1,0) [0|255] "" BMW_I3
 SG_ ACCELERATOR_WORD23_PT_CAN : 16|16@1+ (1,0) [0|65535] "" BMW_I3
 SG_ ACCELERATOR_VALUE_PT_CAN : 16|16@1+ (1,-4096) [0|4000] "" BMW_I3
 SG_ ACCELERATOR_I4_COMPAT_PT_CAN : 16|12@1+ (0.000244,0) [0|2047] "" BMW_I3
CM_ BO_ 217 "Confirmed PT-CAN accelerator-family frame. The first 16 bits remain useful as upstream positive/coast long-intent helper, while bytes 2:3 are now confirmed as the driver accelerator analog field on the i3. Current isolated pedal routes show 4096 at release and 8096 at full pedal, giving a clean 0..4000 working span after subtracting 4096.";
CM_ SG_ 217 ACCEL_RAW_PT_CAN "Best current upstream positive/coast long-intent candidate. Cross-route fit against longitudinalPlan.aTarget on 147/148/170/176/177 shows this raw 16-bit field correlates materially better with positive/coast intent than downstream 59/54 words. Current pragmatic managed-mode medians: POS ~63334, COAST ~63364.";
CM_ SG_ 217 ACCELERATOR_WORD23_PT_CAN "Confirmed raw accelerator word from bytes 2:3 on PT-CAN frame 217. Isolated pedal routes show release ~4096 and full pedal ~8096.";
CM_ SG_ 217 ACCELERATOR_VALUE_PT_CAN "Confirmed driver accelerator analog value on PT-CAN frame 217, derived as bytes2:3 minus 4096. Practical observed range: 0 release to 4000 full pedal.";
CM_ SG_ 217 ACCELERATOR_I4_COMPAT_PT_CAN "Legacy i4-compatible helper view of frame 217. Keep as comparison/support only; current i3 long fitting works better on the raw 16-bit field than on this compressed 12-bit projection.";

BO_ 239 PTCAN_CRUISE_BUTTONS_AUX: 8 BMW_I3
 SG_ CRUISE_BTN_AUX_PT_CAN : 0|16@1+ (1,0) [0|65535] "" BMW_I3
 SG_ CRUISE_BTN_AUX_BYTE_0 : 0|8@1+ (1,0) [0|255] "" BMW_I3
 SG_ CRUISE_BTN_AUX_BYTE_1 : 8|8@1+ (1,0) [0|255] "" BMW_I3
 SG_ BRAKE_PEDAL_WORD23_PT_CAN : 16|16@1+ (1,0) [0|65535] "" BMW_I3
 SG_ BRAKE_PEDAL_WORD56_PT_CAN : 40|16@1+ (1,0) [0|65535] "" BMW_I3
 SG_ BRAKE_PEDAL_I4_COMPAT_PT_CAN : 40|12@1+ (-1,3328) [0|3328] "" BMW_I3
CM_ BO_ 239 "PT-CAN auxiliary frame carrying cruise-button support plus a promising friction-brake analog candidate on bytes 2:3 and 5:6. In the latest parked brake-only route, both 16-bit words sit near 32000 at release and decrease monotonically across light, medium, and strong pedal application. This still needs road validation against regen before promotion to production brake logic.";

BO_ 274 PTCAN_BLINKER_STATE_CANDIDATE: 8 BMW_I3
 SG_ BLINKER_STATE_WORD0_PT_CAN : 0|16@1+ (1,0) [0|65535] "" BMW_I3
 SG_ BLINKER_STATE_BYTE_0 : 0|8@1+ (1,0) [0|255] "" BMW_I3
 SG_ BLINKER_STATE_BYTE_2 : 16|8@1+ (1,0) [0|255] "" BMW_I3
 SG_ BLINKER_STATE_BYTE_4 : 32|8@1+ (1,0) [0|255] "" BMW_I3
 SG_ BLINKER_STATE_BYTE_6 : 48|8@1+ (1,0) [0|255] "" BMW_I3
 SG_ BLINKER_STATE_BYTE_7 : 56|8@1+ (1,0) [0|255] "" BMW_I3
CM_ BO_ 274 "Confirmed PT-CAN state helper used for raw blinker-family reverse work. Byte 6 remains useful as a left/right indicator-state discriminator on src 2, but recent parked seatbelt rechecks no longer support byte 7 as a reliable buckle source.";

BO_ 435 PTCAN_SEATBELT_CANDIDATE_A: 8 BMW_I3
 SG_ PTCAN_SEATBELT_BYTE_4_A : 32|8@1+ (1,0) [0|255] "" BMW_I3
CM_ BO_ 435 "Replicated parked seatbelt routes 0000019c and 0000019d show byte 4 tracking buckle state cleanly on src 2: 0x00 latched, 0x04 unlatched. Use together with frame 663 as a cross-check.";

BO_ 481 PTCAN_DRIVER_DOOR_CANDIDATE: 6 BMW_I3
 SG_ DRIVER_DOOR_STATE_BYTE_2 : 16|8@1+ (1,0) [0|255] "" BMW_I3
CM_ BO_ 481 "Confirmed PT-CAN driver-door frame in current CarState. Latest isolated parked door route and the previous two-open-close route both show byte 2 toggling cleanly between 0 (closed) and 1 (open) on src 2.";

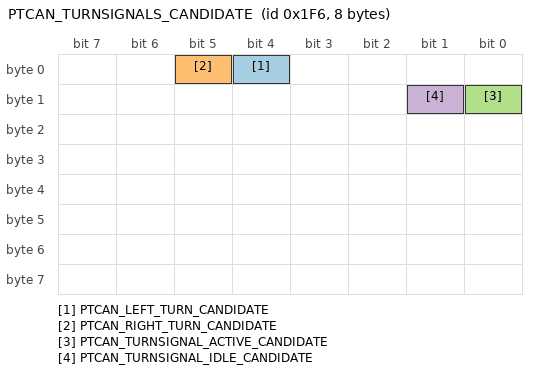
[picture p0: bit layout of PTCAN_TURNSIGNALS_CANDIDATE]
BO_ 502 PTCAN_TURNSIGNALS_CANDIDATE: 8 BMW_I3
 SG_ PTCAN_LEFT_TURN_CANDIDATE : 4|1@1+ (1,0) [0|1] "" BMW_I3
 SG_ PTCAN_RIGHT_TURN_CANDIDATE : 5|1@0+ (1,0) [0|1] "" BMW_I3
 SG_ PTCAN_TURNSIGNAL_ACTIVE_CANDIDATE : 8|1@0+ (1,0) [0|1] "" BMW_I3
 SG_ PTCAN_TURNSIGNAL_IDLE_CANDIDATE : 9|1@0+ (1,0) [0|1] "" BMW_I3
CM_ BO_ 502 "Raw PT-CAN turn-signal helper aligned with the smnogar BMW KCAN DBC. This frame is present on recent i3 routes, but the current i3 parser still prefers frame 274 because it is more robust across the existing captures. Keep 502 as a raw comparison/helper source only for now.";

BO_ 538 PTCAN_BRAKE_PEDAL_CANDIDATE: 3 BMW_I3
 SG_ PTCAN_BRAKE_PEDAL_BYTE_0 : 0|8@1+ (1,0) [0|255] "" BMW_I3
CM_ BO_ 538 "PT-CAN decel / stop-lamp / brake-related helper candidate. It still moves with brake events, but later isolated gas work showed it is not specific enough to be treated as the true pedal source. Keep it as a secondary helper only; brake analog now comes from frame 239 bytes 5:6.";

BO_ 663 PTCAN_SEATBELT_CANDIDATE_B: 7 BMW_I3
 SG_ PTCAN_SEATBELT_BYTE_2_B : 16|8@1+ (1,0) [0|255] "" BMW_I3
CM_ BO_ 663 "Replicated parked seatbelt routes 0000019c and 0000019d show byte 2 tracking buckle state cleanly on src 2: 0xF1 latched, 0xF0 unlatched. Use together with frame 435 as a cross-check.";

BO_ 415 PTCAN_CRUISE_BUTTONS_MAIN: 8 BMW_I3
 SG_ CRUISE_BTN_MAIN_PT_CAN : 16|16@1+ (1,0) [0|65535] "" BMW_I3
 SG_ CRUISE_BTN_MAIN_BYTE_2 : 16|8@1+ (1,0) [0|255] "" BMW_I3
 SG_ CRUISE_BTN_MAIN_BYTE_3 : 24|8@1+ (1,0) [0|255] "" BMW_I3
CM_ BO_ 415 "Primary PT-CAN cruise-button frame. Bytes 2-3 changed cleanly across SET, RES, and distance-button presses with stable idle values, making this the best current main cruise-button source on CAN src 2. Current CarState uses this frame for SET/RES button events; +/- speed and distance semantics remain unresolved.";

BO_ 769 PTCAN_STEERING_WHEEL_COMPANION_CANDIDATE: 7 BMW_I3
 SG_ PTCAN_STEERING_WHEEL_COMPANION_RAW : 16|16@1+ (1,0) [0|65535] "" BMW_I3
 SG_ PTCAN_STEERING_WHEEL_COMPANION_ANGLE_I3_CAL : 16|16@1+ (0.03540,-1159.28) [-720|720] "deg" BMW_I3
CM_ BO_ 769 "Low-rate PT-CAN steering-angle companion on CAN src 2. Treat 770 as the primary live steering-wheel-angle feedback and 769 as a decimated/filtered companion. Current linear scale is centered around raw ~32748 and validated live against about +/-180 deg wheel checkpoints, with raw 37850 ~= +180 deg and raw 27677 ~= -180 deg. Keep the exact OEM semantic split between 769 and 770 open until a dedicated visual steering calibration route confirms the final mapping.";

BO_ 770 PTCAN_STEERING_WHEEL_CANDIDATE: 7 BMW_I3
 SG_ PTCAN_STEERING_WHEEL_RAW : 16|16@1+ (1,0) [0|65535] "" BMW_I3
 SG_ PTCAN_STEERING_WHEEL_ANGLE_I3_CAL : 16|16@1+ (0.03540,-1159.28) [-720|720] "deg" BMW_I3
CM_ BO_ 770 "Primary PT-CAN steering-wheel-angle candidate on CAN src 2. Raw bytes 2-3 still correlate strongest in the full raw scan and remain the best current live steering feedback source on the i3. Current linear scale is centered around raw ~32748 and validated live against about +/-180 deg wheel checkpoints, with raw 37850 ~= +180 deg and raw 27677 ~= -180 deg. Keep the exact OEM signal name and final physical scaling open until a dedicated visual steering calibration route confirms the mapping.";

BO_ 796 PTCAN_BRAKE_PRESSED_CANDIDATE: 8 BMW_I3
 SG_ BRAKE_PRESSED_RAW_PT_CAN : 0|16@1+ (1,0) [0|65535] "" BMW_I3
 SG_ BRAKE_PRESSED_BYTE_0_PT_CAN : 0|8@1+ (1,0) [0|255] "" BMW_I3
 SG_ BRAKE_PRESSED_BYTE_1_PT_CAN : 8|8@1+ (1,0) [0|255] "" BMW_I3
CM_ BO_ 796 "PT-CAN brake/negative-intent helper frame. Byte 1 still separates long negative/coast families and remains useful for longitudinal reverse work, but recent isolated parked brake route 000001a0 shows it is not a reliable standalone brakePressed source.";
CM_ SG_ 796 BRAKE_PRESSED_RAW_PT_CAN "Best current upstream negative/brake long-intent candidate on PT-CAN. Cross-route fit against longitudinalPlan.aTarget shows this frame separates negative intent more cleanly than downstream 54/59 words, especially when combined with byte1.";
CM_ SG_ 796 BRAKE_PRESSED_BYTE_1_PT_CAN "Strongest current coarse negative/brake discriminator. Current pragmatic managed-mode negative bucket sits near byte1 ~13, while coast/positive windows stay near the idle range (~0x20..0x2E).";

BO_ 1017 PTCAN_GEAR_CANDIDATE: 8 BMW_I3
 SG_ PTCAN_GEAR_RAW_CANDIDATE : 50|3@0+ (1,0) [0|7] "" BMW_I3
 SG_ PTCAN_GEAR_I4_COMPAT : 50|3@0+ (1,0) [0|7] "" BMW_I3
CM_ BO_ 1017 "Raw PT-CAN gear helper aligned with the smnogar BMW KCAN DBC. This frame is present on recent i3 routes, but the current captures do not separate all gear states cleanly enough to replace the existing drive-state logic. Keep it as a raw/helper source for future gear validation only.";
